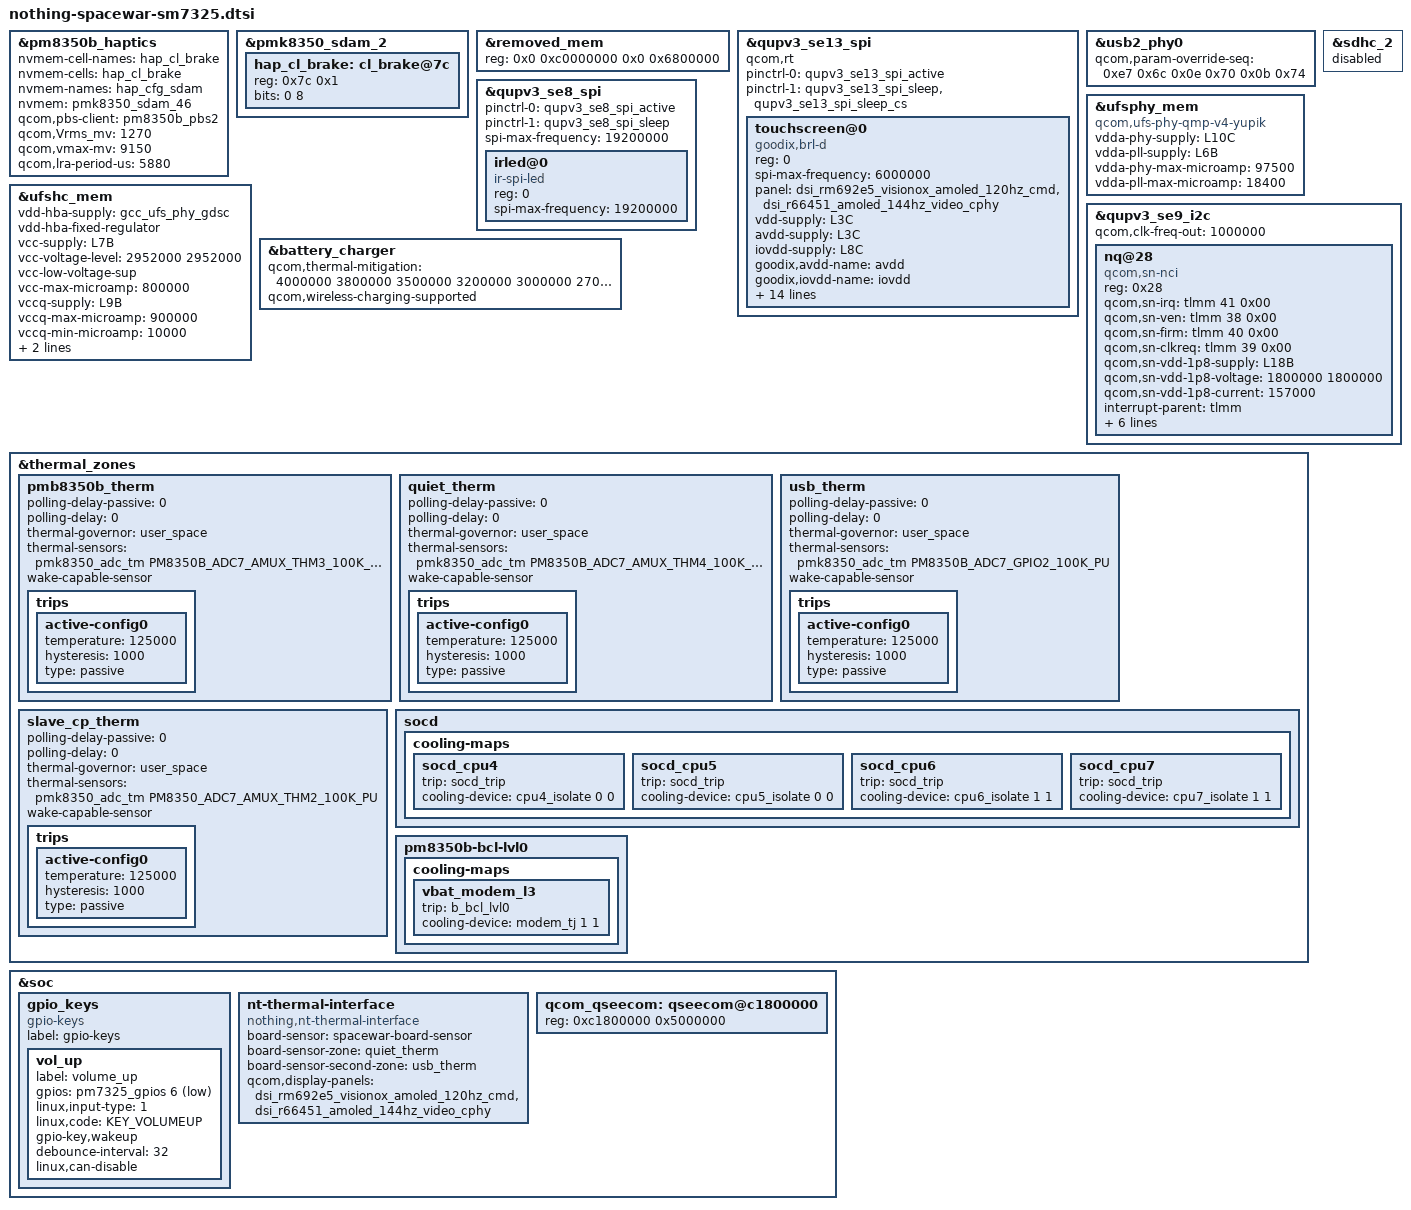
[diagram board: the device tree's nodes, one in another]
// nothing-spacewar-sm7325.dtsi
// Nothing Phone (1) "spacewar" (SM7325 "Yupik")
//

#include "yupik-abra-common-overlay.dtsi"
#include "nothing-spacewar-pinctrl.dtsi"
#include "nothing-spacewar-audio-overlay.dtsi"
#include "display/nothing-sm7325-sde-display.dtsi"
#include <dt-bindings/gpio/gpio.h>
#include <dt-bindings/input/input.h>
#include <dt-bindings/iio/qcom,spmi-adc7-pm7325.h>
#include <dt-bindings/iio/qcom,spmi-adc7-smb139x.h>
#include <dt-bindings/iio/qcom,spmi-adc7-pm8350b.h>

&pm8350b_haptics {
	nvmem-cell-names = "hap_cl_brake";
	nvmem-cells = <&hap_cl_brake>;
	nvmem-names = "hap_cfg_sdam";
	nvmem = <&pmk8350_sdam_46>;
	qcom,pbs-client = <&pm8350b_pbs2>;
	qcom,Vrms_mv = <1270>;
	qcom,vmax-mv = <9150>;
	qcom,lra-period-us = <5880>;
	status = "ok";

};

&pmk8350_sdam_2 {
	hap_cl_brake: cl_brake@7c {
		reg = <0x7c 0x1>;
		bits = <0 8>;
	};
};

&removed_mem {
	reg = <0x0 0xc0000000 0x0 0x6800000>;
};

&qupv3_se13_spi {
	status = "ok";
	qcom,rt;
	pinctrl-names = "default", "sleep";
	pinctrl-0 = <&qupv3_se13_spi_active>;	/* from yupik base */
	pinctrl-1 = <&qupv3_se13_spi_sleep &qupv3_se13_spi_sleep_cs>;
	#address-cells = <1>;
	#size-cells = <0>;

	touchscreen@0 {
		compatible = "goodix,brl-d", "focaltech,fts_ts";
		reg = <0>;
		spi-max-frequency = <6000000>;

		panel = <&dsi_rm692e5_visionox_amoled_120hz_cmd
			 &dsi_r66451_amoled_144hz_video_cphy>;

		/* shared rails */
		vdd-supply = <&L3C>;		/* fts AVDD 3.3V */
		avdd-supply = <&L3C>;		/* goodix AVDD  */
		iovdd-supply = <&L8C>;		/* both, 1.8V   */

		/* Goodix */
		goodix,avdd-name = "avdd";
		goodix,iovdd-name = "iovdd";
		goodix,reset-gpio = <&tlmm 105 0x00>;
		goodix,irq-gpio = <&tlmm 81 0x2800>;
		goodix,irq-flags = <2>;
		goodix,panel-max-x = <1080>;
		goodix,panel-max-y = <2400>;
		goodix,panel-max-w = <255>;
		goodix,panel-max-p = <4096>;
		goodix,pen-enable;
		goodix,firmware-name = "goodix_firmware.bin";
		goodix,config-name = "goodix_cfg_group.bin";

		/* Focaltech */
		focaltech,reset-gpio = <&tlmm 105 0x00>;
		focaltech,irq-gpio = <&tlmm 81 0x2800>;
		focaltech,max-touch-number = <10>;
		focaltech,display-coords = <0 0 1080 2400>;
	};
};

&usb2_phy0 {
	qcom,param-override-seq =
		<0xe7 0x6c  	/* override_x0 */
		 0x0e 0x70  	/* override_x1 */
		 0x0b 0x74>;	/* override x2 */
};

&qupv3_se8_spi {
	status = "okay";
	pinctrl-names = "default", "sleep";
	pinctrl-0 = <&qupv3_se8_spi_active>;
	pinctrl-1 = <&qupv3_se8_spi_sleep>;
	spi-max-frequency = <19200000>;
	#address-cells = <1>;
	#size-cells = <0>;

	irled@0 {
		compatible = "ir-spi-led";
		reg = <0>;
		spi-max-frequency = <19200000>;
	};
};

&sdhc_2 {
	status = "disabled";
};

&ufsphy_mem {
	compatible = "qcom,ufs-phy-qmp-v4-yupik";

	vdda-phy-supply = <&L10C>;
	vdda-pll-supply = <&L6B>;
	vdda-phy-max-microamp = <97500>;
	vdda-pll-max-microamp = <18400>;

	status = "ok";
};

&ufshc_mem {
	vdd-hba-supply = <&gcc_ufs_phy_gdsc>;
	vdd-hba-fixed-regulator;

	vcc-supply = <&L7B>;
	vcc-voltage-level = <2952000 2952000>;
	vcc-low-voltage-sup;
	vcc-max-microamp = <800000>;

	/*
	 * vccq (L9B) also controls the eLDO supplying VCCQ2 (UFS2.2).
	 * Do not change/remove these entries.
	 */
	vccq-supply = <&L9B>;
	vccq-max-microamp = <900000>;
	vccq-min-microamp = <10000>;

	qcom,vddp-ref-clk-supply = <&L9B>;
	qcom,vddp-ref-clk-max-microamp = <100>;

	status = "ok";
};

&qupv3_se9_i2c {
	status = "ok";
	qcom,clk-freq-out = <1000000>;
	#address-cells = <1>;
	#size-cells = <0>;

	nq@28 {
		compatible = "qcom,sn-nci";
		reg = <0x28>;
		qcom,sn-irq = <&tlmm 41 0x00>;
		qcom,sn-ven = <&tlmm 38 0x00>;
		qcom,sn-firm = <&tlmm 40 0x00>;
		qcom,sn-clkreq = <&tlmm 39 0x00>;
		qcom,sn-vdd-1p8-supply = <&L18B>;
		qcom,sn-vdd-1p8-voltage = <1800000 1800000>;
		qcom,sn-vdd-1p8-current = <157000>;
		interrupt-parent = <&tlmm>;
		interrupts = <41 0>;
		interrupt-names = "nfc_irq";
		pinctrl-names = "nfc_active", "nfc_suspend";
		pinctrl-0 = <&nfc_int_active &nfc_enable_active
				&nfc_clkreq_active &nfc_dwl_active>;
		pinctrl-1 = <&nfc_int_suspend &nfc_enable_suspend
				&nfc_clkreq_suspend &nfc_dwl_suspend>;
	};
};

&battery_charger {
	/* 15 steps -> cooling_device "battery" max_state=15 (matches your log) */
	qcom,thermal-mitigation = <4000000 3800000 3500000 3200000 3000000
				2700000 2500000 2200000 2000000 1700000
				1500000 1200000 1000000 800000 500000>;
	qcom,wireless-charging-supported;
};

&thermal_zones {
	/* Nothing thermal-engine probes: user_space governor + wake-capable */

	pmb8350b_therm {
		polling-delay-passive = <0>;
		polling-delay = <0>;
		thermal-governor = "user_space";
		thermal-sensors = <&pmk8350_adc_tm PM8350B_ADC7_AMUX_THM3_100K_PU>;
		wake-capable-sensor;
		trips {
			active-config0 {
				temperature = <125000>;
				hysteresis = <1000>;
				type = "passive";
			};
		};
	};

	quiet_therm {
		polling-delay-passive = <0>;
		polling-delay = <0>;
		thermal-governor = "user_space";
		thermal-sensors = <&pmk8350_adc_tm PM8350B_ADC7_AMUX_THM4_100K_PU>;
		wake-capable-sensor;
		trips {
			active-config0 {
				temperature = <125000>;
				hysteresis = <1000>;
				type = "passive";
			};
		};
	};

	usb_therm {
		polling-delay-passive = <0>;
		polling-delay = <0>;
		thermal-governor = "user_space";
		thermal-sensors = <&pmk8350_adc_tm PM8350B_ADC7_GPIO2_100K_PU>;
		wake-capable-sensor;
		trips {
			active-config0 {
				temperature = <125000>;
				hysteresis = <1000>;
				type = "passive";
			};
		};
	};

	slave_cp_therm {
		polling-delay-passive = <0>;
		polling-delay = <0>;
		thermal-governor = "user_space";
		thermal-sensors = <&pmk8350_adc_tm PM8350_ADC7_AMUX_THM2_100K_PU>;
		wake-capable-sensor;
		trips {
			active-config0 {
				temperature = <125000>;
				hysteresis = <1000>;
				type = "passive";
			};
		};
	};

	/* SoD backplate mitigation (keep — labels verified below) */
	socd {
		cooling-maps {
			socd_cpu4 { trip = <&socd_trip>; cooling-device = <&cpu4_isolate 0 0>; };
			socd_cpu5 { trip = <&socd_trip>; cooling-device = <&cpu5_isolate 0 0>; };
			socd_cpu6 { trip = <&socd_trip>; cooling-device = <&cpu6_isolate 1 1>; };
			socd_cpu7 { trip = <&socd_trip>; cooling-device = <&cpu7_isolate 1 1>; };
		};
	};

	pm8350b-bcl-lvl0 {
		cooling-maps {
			vbat_modem_l3 { trip = <&b_bcl_lvl0>; cooling-device = <&modem_tj 1 1>; };
		};
	};
};

&soc {
	gpio_keys {
		compatible = "gpio-keys";
		label = "gpio-keys";
		/* pinctrl removed: PM7325 GPIO needs no pinctrl;
		 * &key_vol_up_default label is not defined anywhere */
		vol_up {
			label = "volume_up";
			gpios = <&pm7325_gpios 6 GPIO_ACTIVE_LOW>;
			linux,input-type = <1>;
			linux,code = <KEY_VOLUMEUP>;
			gpio-key,wakeup;
			debounce-interval = <32>;
			linux,can-disable;
		};
	};

	nt-thermal-interface {
		compatible = "nothing,nt-thermal-interface";
		board-sensor = "spacewar-board-sensor";
		/* NEW: zones the driver live-reads for board_sensor_temp */
		board-sensor-zone = "quiet_therm";
		board-sensor-second-zone = "usb_therm";
		qcom,display-panels = <&dsi_rm692e5_visionox_amoled_120hz_cmd
					&dsi_r66451_amoled_144hz_video_cphy>;
	};

	qcom_qseecom: qseecom@c1800000 {
		reg = <0xc1800000 0x5000000>;
		reg-names = "secapp-region";
	};
};
